# RL6678_IP_SVD register map
Vendor: Realtek
Registers are 32-bit, read-write, reset 0x0 unless marked. A register's access mark holds for its fields unless they carry their own. Offsets are from the block's base; [hi:lo] are bit positions; {n}, {i} and the like mark numbered series.

## DDRCF_REG
Base 0x41101000
0x00 FE_DIR_0 ro — Design name register
  [31:0] design_name — Design name is RXI-316
0x04 FE_DIR_1 ro reset 0x100 — Design version register
  [31:0] design_version
0x08 FE_DIR_2 ro — Design revision register
  [31:0] design_revision
0x0C FE_DIR_3 ro — Instance number register
  [31:0] design_instance — Instance number
0x10 FE_DIR_4 ro reset 0x2019 — Implementation year
  [31:0] impl_year — Year of design generation
0x14 FE_DIR_5 ro — Implementation date
  [31:0] impl_date — Date of design generation (MM_DD_HH_mm)
0x18 FE_DIR_6 ro — Developer
  [31:0] developer — Developer of design generation (RXXXX)
0x1C FE_DIR_7 ro — Project number
  [31:0] proj_number — Project number (RL number)
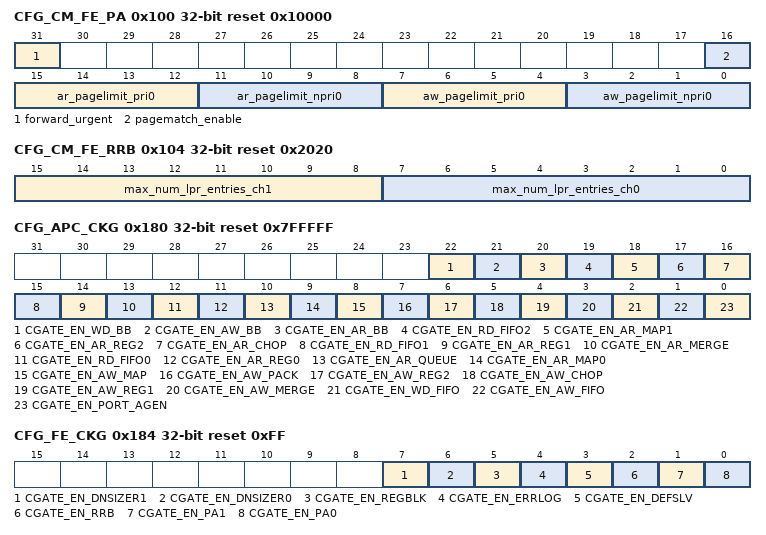
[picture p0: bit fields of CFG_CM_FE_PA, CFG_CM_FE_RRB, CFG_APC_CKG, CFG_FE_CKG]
0x100 CFG_CM_FE_PA reset 0x10000 — Port arbiter page limitation value
  [31] forward_urgent — Forward urgent signals to backend through go_to_first
  [16] pagematch_enable — Choose page match transaction continuously
  [15:12] ar_pagelimit_pri0 — The signal width of priority0 page-match limit value
  [11:8] ar_pagelimit_npri0 — The signal width of non-priority0 page-match limit value
  [7:4] aw_pagelimit_pri0 — The signal width of priority0 page-match limit value
  [3:0] aw_pagelimit_npri0 — The signal width of non-priority0 page-match limit value
0x104 CFG_CM_FE_RRB reset 0x2020 — RRB LP read entry number
  [15:8] max_num_lpr_entries_ch1 — Maximum number of free slots reserved for LP read commands in channel 1.
  [7:0] max_num_lpr_entries_ch0 — Maximum number of free slots reserved for LP read commands in channel 0.
0x180 CFG_APC_CKG reset 0x7FFFFF — Auto clock gating control register for APC
  [22] CGATE_EN_WD_BB — Enable auto clock gating of wd bb reg in all APC
  [21] CGATE_EN_AW_BB — Enable auto clock gating of aw bb reg in all APC
  [20] CGATE_EN_AR_BB — Enable auto clock gating of ar bb reg in all APC
  [19] CGATE_EN_RD_FIFO2 — Enable auto clock gating of rd fifo2 in all APC
  [18] CGATE_EN_AR_MAP1 — Enable auto clock gating of ar addmap1 in all APC
  [17] CGATE_EN_AR_REG2 — Enable auto clock gating of ar reg2 in all APC
  [16] CGATE_EN_AR_CHOP — Enable auto clock gating of ar chop in all APC
  [15] CGATE_EN_RD_FIFO1 — Enable auto clock gating of rd fifo1 in all APC
  [14] CGATE_EN_AR_REG1 — Enable auto clock gating of ar reg1 in all APC
  [13] CGATE_EN_AR_MERGE — Enable auto clock gating of ar merge in all APC
  [12] CGATE_EN_RD_FIFO0 — Enable auto clock gating of rd FIFO0 in all APC
  [11] CGATE_EN_AR_REG0 — Enable auto clock gating of ar reg0 in all APC
  [10] CGATE_EN_AR_QUEUE — Enable auto clock gating of ar queue in all APC
  [9] CGATE_EN_AR_MAP0 — Enable auto clock gating of ar addmap0 in all APC
  [8] CGATE_EN_AW_MAP — Enable auto clock gating of aw addmap in all APC
  [7] CGATE_EN_AW_PACK — Enable auto clock gating of aw pack in all APC
  [6] CGATE_EN_AW_REG2 — Enable auto clock gating of aw reg2 in all APC
  [5] CGATE_EN_AW_CHOP — Enable auto clock gating of aw chop in all APC
  [4] CGATE_EN_AW_REG1 — Enable auto clock gating of aw reg1 in all APC
  [3] CGATE_EN_AW_MERGE — Enable auto clock gating of aw merge in all APC
  [2] CGATE_EN_WD_FIFO — Enable auto clock gating of wd FIFO in all APC
  [1] CGATE_EN_AW_FIFO — Enable auto clock gating of aw FIFO in all APC
  [0] CGATE_EN_PORT_AGEN — Enable auto clock gating of port agent in all APC
0x184 CFG_FE_CKG reset 0xFF — Auto clock gating control register for FE
  [7] CGATE_EN_DNSIZER1 — Enable auto clock gating of channel 1 dnsizer2
  [6] CGATE_EN_DNSIZER0 — Enable auto clock gating of channel 0 dnsizer2
  [5] CGATE_EN_REGBLK — Enable auto clock gating of register block except ckg registers
  [4] CGATE_EN_ERRLOG — Enable auto clock gating of error log
  [3] CGATE_EN_DEFSLV — Enable auto clock gating of default slave
  [2] CGATE_EN_RRB — Enable auto clock gating of rrb
  [1] CGATE_EN_PA1 — Enable auto clock gating of port arbiter 1
  [0] CGATE_EN_PA0 — Enable auto clock gating of port arbiter 0
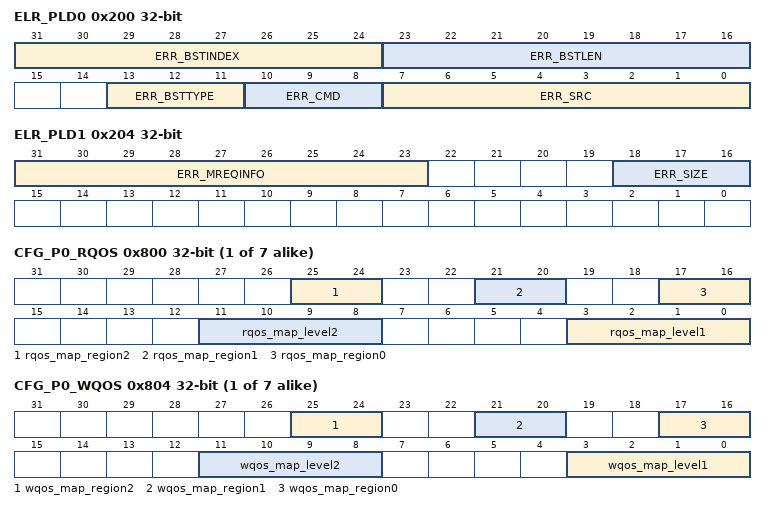
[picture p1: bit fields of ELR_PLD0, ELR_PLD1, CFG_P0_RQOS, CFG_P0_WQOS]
0x200 ELR_PLD0 ro — Error transaction information 0
  [31:24] ERR_BSTINDEX — Burst index inside a burst that trigger fault. Always 0 in RXI-316
  [23:16] ERR_BSTLEN — Burst length of error transaction after chopped.
  [13:11] ERR_BSTTYPE — BurstSeq of the error request.
  [10:8] ERR_CMD — Cmd of the error request. 3'h1: write 3'h2: read
  [7:0] ERR_SRC — Error source. Always 0 in RXI-316
0x204 ELR_PLD1 ro — Error transaction information 1
  [31:23] ERR_MREQINFO — Request information {axlock, axprot,axcache} of error transaction
  [18:16] ERR_SIZE — AXI Size of the error request.
0x208 ELR_ID ro — ID of error transaction
  [31:0] ERR_ID — AXI ID of the error request. This ID combines AXI ID and port ID
0x20C ELR_ADR0 ro — Lower part address of error transaction
  [31:0] Lower_part_of_address — Address[31:0] of the error request.
0x210 ELR_ADR1 ro — Higher part address of error transaction
  [31:0] Higher_part_of_address — Address[63:32] of the error request.
0x214 ELR_CODE ro — Error type
  [7:0] Error_Core — The error code of error request. 8'b0: Secure fault
0x23C ELR_CTRL wo — Error interrupt clear
  [0] ELR_INTR_CLR — Error log interrupt clear. Writing 1'b1 to the register will trigger a 1-cycle pulse interrupt clear. It has to write 1'b1 to this register every time when the error exception occurs. Note that this register is write-only, the return value of reading this register is meaningless
{0x800+0x40*i} CFG_P{i}_RQOS (i=0..6) — Port{i} Read QoS value
  [25:24] rqos_map_region2 — Traffic class of region 2. 0: LPR 1: VPR 2: HPR
  [21:20] rqos_map_region1 — Traffic class of region 1. 0: LPR 1: VPR 2: HPR
  [17:16] rqos_map_region0 — Traffic class of region 0. 0: LPR 1: VPR 2: HPR
  [11:8] rqos_map_level2 — Separation level2 indicating the end of region 1 mapping. Region1 starts from (rqos_map_level1 + 1) to rqos_map_level2. Region2 starts from (rqos_map_level2 + 1) to 15. e.g. {rqos_map_level1, rqos_map_level2, rqos_map_region0, rqos_map_region1, rqos_map_region0} = {6, 13, 0, 1, 2}. QoS 0~6 is LPR, QoS 7~13 is VPR, and QoS 14~15 is HRP.
  [3:0] rqos_map_level1 — Separation level1 indicating the end of region 0 mapping. Region0 starts from 0 to rqos_map_level1. e.g. rqos_map_level1 is 6, and rqos_map_region0 is 0. QoS 0 ~ 6 is LPR.
{0x804+0x40*i} CFG_P{i}_WQOS (i=0..6) — Port{i} Write QoS value
  [25:24] wqos_map_region2 — Traffic class of region 2. 0: LPW 1: VPW
  [21:20] wqos_map_region1 — Traffic class of region 1. 0: LPW 1: VPW
  [17:16] wqos_map_region0 — Traffic class of region 0. 0: LPW 1: VPW
  [11:8] wqos_map_level2 — Separation level2 indicating the end of region 1 mapping.
  [3:0] wqos_map_level1 — Separation level1 indicating the end of region 0 mapping.
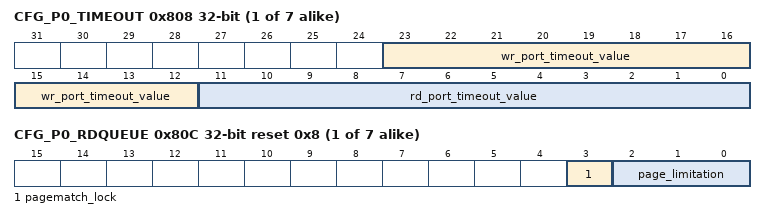
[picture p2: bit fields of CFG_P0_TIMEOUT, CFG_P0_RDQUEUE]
{0x808+0x40*i} CFG_P{i}_TIMEOUT (i=0..6) — Port{i} timeout value
  [23:12] wr_port_timeout_value — Write port timeout counter
  [11:0] rd_port_timeout_value — Read port timeout counter
{0x80C+0x40*i} CFG_P{i}_RDQUEUE reset 0x8 (i=0..6) — Port{i} read queue arbitration
  [3] pagematch_lock — Lock page match port for dual port
  [2:0] page_limitation — page-match limitation value
{0x810+0x40*i} CFG_P{i}_EXPIRYL (i=0..6) — Port{i} expiry value (Bit31 ~ Bit0)
  [31:0] expiry_time_low — Expiry time bit 31 ~ 0 of a transaction. The maximum available value depends on STAMP_WIDTH (2^STAMP_WIDTH).
{0x814+0x40*i} CFG_P{i}_EXPIRYH (i=0..6) — Port{i} expiry value (Bit63 ~ Bit32)
  [31:0] expiry_time_high — Expiry time bit 63 ~ 32 of a transaction. The maximum available value depends on STAMP_WIDTH (2^STAMP_WIDTH).
{0x818+0x40*i} CFG_P{i}_PORTCTRL reset 0x1 (i=0..6) — Port{i} control
  [0] block_command_request — Blocks new transactions from entering the front-end. 1: block AR and AW channels. 0: turn on AR and AW channels
{0x81C+0x40*i} CFG_P{i}_PORTSTATS ro (i=0..6) — Port{i} status
  [0] block_command_status — AR and AW channel blocking status. 1: both AR and AW are blocked. 0: any of them is not blocked.
